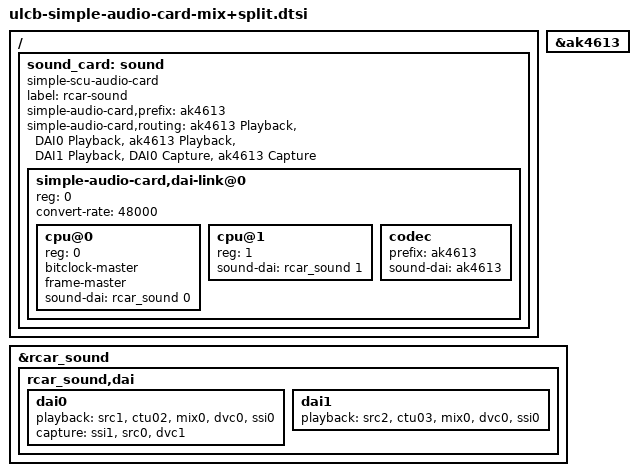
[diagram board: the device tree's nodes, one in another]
/ {
	sound_card: sound {
		#address-cells = <1>;
		#size-cells = <0>;
		compatible = "simple-scu-audio-card";
		label = "rcar-sound";
		simple-audio-card,prefix  = "ak4613";
		simple-audio-card,routing = "ak4613 Playback", "DAI0 Playback",
					    "ak4613 Playback", "DAI1 Playback",
					    "DAI0 Capture",    "ak4613 Capture";
		simple-audio-card,dai-link@0 {
			#address-cells = <1>;
			#size-cells = <0>;
			reg = <0>;
			convert-rate = <48000>;
			cpu@0 {
				reg = <0>;
				bitclock-master;
				frame-master;
				sound-dai = <&rcar_sound 0>;
			};
			cpu@1 {
				reg = <1>;
				sound-dai = <&rcar_sound 1>;
			};
			codec {
				prefix = "ak4613";
				sound-dai = <&ak4613>;
			};
		};
	};
};
&ak4613 {
	#sound-dai-cells = <0>;
};
&rcar_sound {
	#sound-dai-cells = <1>;
	rcar_sound,dai {
		dai0 {
			playback = <&src1 &ctu02 &mix0 &dvc0 &ssi0>;
			capture  = <&ssi1 &src0 &dvc1>;
		};
		dai1 {
			playback = <&src2 &ctu03 &mix0 &dvc0 &ssi0>;
		};
	};
};
